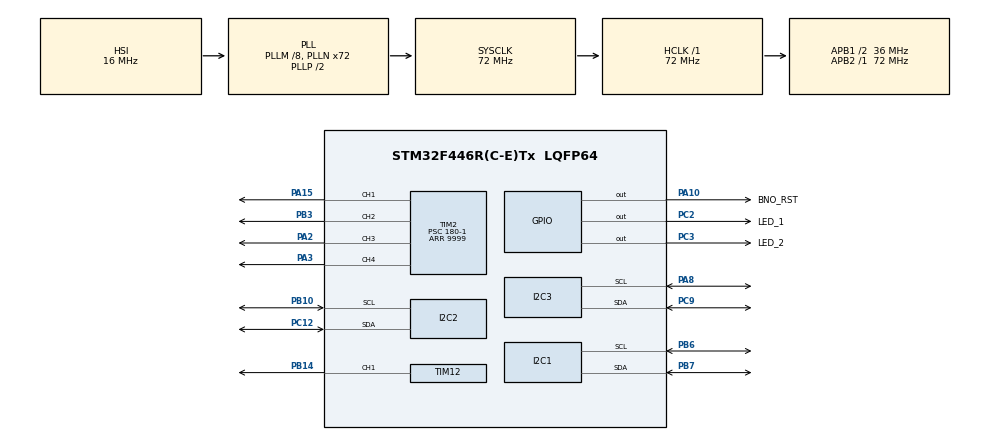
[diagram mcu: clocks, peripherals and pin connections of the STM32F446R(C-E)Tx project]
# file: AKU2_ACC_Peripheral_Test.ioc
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Mcu.Family=STM32F4
Mcu.Name=STM32F446R(C-E)Tx
Mcu.Package=LQFP64
NVIC.PriorityGroup=NVIC_PRIORITYGROUP_4
NVIC.TIM1_UP_TIM10_IRQn=true\:15\:0\:false\:false\:true\:false\:true\:true
NVIC.TimeBase=TIM1_UP_TIM10_IRQn
NVIC.TimeBaseIP=TIM1
PA10.GPIO_Label=BNO_RST
PA10.GPIO_PuPd=GPIO_PULLUP
PA10.PinState=GPIO_PIN_RESET
PA10.Signal=GPIO_Output
PA13.GPIO_Label=TMS
PA13.Mode=Serial_Wire
PA13.Signal=SYS_JTMS-SWDIO
PA14.GPIO_Label=TCK
PA14.Mode=Serial_Wire
PA14.Signal=SYS_JTCK-SWCLK
PA15.Signal=S_TIM2_CH1_ETR
PA2.Signal=S_TIM2_CH3
PA3.Signal=S_TIM2_CH4
PA8.Mode=I2C
PA8.Signal=I2C3_SCL
PB10.Mode=I2C
PB10.Signal=I2C2_SCL
PB14.Signal=S_TIM12_CH1
PB3.Signal=S_TIM2_CH2
PB6.Mode=I2C
PB6.Signal=I2C1_SCL
PB7.Mode=I2C
PB7.Signal=I2C1_SDA
PC12.Mode=I2C
PC12.Signal=I2C2_SDA
PC2.GPIO_Label=LED_1
PC2.Signal=GPIO_Output
PC3.GPIO_Label=LED_2
PC3.Signal=GPIO_Output
PC9.Mode=I2C
PC9.Signal=I2C3_SDA
ProjectManager.HeapSize=0x200
ProjectManager.StackSize=0x400
ProjectManager.TargetToolchain=STM32CubeIDE
RCC.48MHZClocksFreq_Value=84000000
RCC.AHBFreq_Value=72000000
RCC.APB1CLKDivider=RCC_HCLK_DIV2
RCC.APB1Freq_Value=36000000
RCC.APB1TimFreq_Value=72000000
RCC.APB2Freq_Value=72000000
RCC.APB2TimFreq_Value=72000000
RCC.CortexFreq_Value=72000000
RCC.FLatency-AdvancedSettings=FLASH_LATENCY_2
RCC.HCLKFreq_Value=72000000
RCC.HSE_VALUE=8000000
RCC.HSI_VALUE=16000000
RCC.PLLM=8
RCC.PLLN=72
RCC.PLLQ=3
RCC.PLLSourceVirtual=RCC_PLLSOURCE_HSI
RCC.SYSCLKFreq_VALUE=72000000
RCC.SYSCLKSource=RCC_SYSCLKSOURCE_PLLCLK
RCC.USBFreq_Value=48000000
RCC.VCOOutputFreq_Value=144000000
SH.S_TIM12_CH1.0=TIM12_CH1,PWM Generation1 CH1
SH.S_TIM2_CH1_ETR.0=TIM2_CH1,PWM Generation1 CH1
SH.S_TIM2_CH2.0=TIM2_CH2,PWM Generation2 CH2
SH.S_TIM2_CH3.0=TIM2_CH3,PWM Generation3 CH3
SH.S_TIM2_CH4.0=TIM2_CH4,PWM Generation4 CH4
TIM12.Channel-PWM\ Generation1\ CH1=TIM_CHANNEL_1
TIM12.Period=9999
TIM12.Prescaler=180-1
TIM2.Channel-PWM\ Generation1\ CH1=TIM_CHANNEL_1
TIM2.Channel-PWM\ Generation2\ CH2=TIM_CHANNEL_2
TIM2.Channel-PWM\ Generation3\ CH3=TIM_CHANNEL_3
TIM2.Channel-PWM\ Generation4\ CH4=TIM_CHANNEL_4
TIM2.Period=9999
TIM2.Prescaler=180-1
VP_SYS_VS_tim1.Mode=TIM1
board=NUCLEO-F446RE

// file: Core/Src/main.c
/* USER CODE BEGIN Header */
/**
  ******************************************************************************
  * @file           : main.c
  * @brief          : Main program body
  ******************************************************************************
  * @attention
  *
  * Copyright (c) 2024 STMicroelectronics.
  * All rights reserved.
  *
  * This software is licensed under terms that can be found in the LICENSE file
  * in the root directory of this software component.
  * If no LICENSE file comes with this software, it is provided AS-IS.
  *
  ******************************************************************************
  */
/* USER CODE END Header */
#include "main.h"
#include "i2c.h"
#include "tim.h"
#include "gpio.h"

void SystemClock_Config(void);

int main(void)
{

  /* MCU Configuration--------------------------------------------------------*/

  /* Reset of all peripherals, Initializes the Flash interface and the Systick. */
  HAL_Init();

  /* Configure the system clock */
  SystemClock_Config();

  /* Initialize all configured peripherals */
  MX_GPIO_Init();
  MX_I2C1_Init();
  MX_I2C3_Init();
  MX_TIM2_Init();
  MX_TIM12_Init();
  MX_I2C2_Init();
  /* USER CODE BEGIN 2 */
  init_bhi360();
  /* USER CODE END 2 */

  /* Infinite loop */
  /* USER CODE BEGIN WHILE */
  while (1)
  {
	  read_bhi360();
    /* USER CODE END WHILE */

  }
}

void SystemClock_Config(void)
{
  RCC_OscInitTypeDef RCC_OscInitStruct = {0};
  RCC_ClkInitTypeDef RCC_ClkInitStruct = {0};

  /** Configure the main internal regulator output voltage
  */
  __HAL_RCC_PWR_CLK_ENABLE();
  __HAL_PWR_VOLTAGESCALING_CONFIG(PWR_REGULATOR_VOLTAGE_SCALE3);

  /** Initializes the RCC Oscillators according to the specified parameters
  * in the RCC_OscInitTypeDef structure.
  */
  RCC_OscInitStruct.OscillatorType = RCC_OSCILLATORTYPE_HSI;
  RCC_OscInitStruct.HSIState = RCC_HSI_ON;
  RCC_OscInitStruct.HSICalibrationValue = RCC_HSICALIBRATION_DEFAULT;
  RCC_OscInitStruct.PLL.PLLState = RCC_PLL_ON;
  RCC_OscInitStruct.PLL.PLLSource = RCC_PLLSOURCE_HSI;
  RCC_OscInitStruct.PLL.PLLM = 8;
  RCC_OscInitStruct.PLL.PLLN = 72;
  RCC_OscInitStruct.PLL.PLLP = RCC_PLLP_DIV2;
  RCC_OscInitStruct.PLL.PLLQ = 3;
  RCC_OscInitStruct.PLL.PLLR = 2;
  if (HAL_RCC_OscConfig(&RCC_OscInitStruct) != HAL_OK)
  {
    Error_Handler();
  }

  /** Initializes the CPU, AHB and APB buses clocks
  */
  RCC_ClkInitStruct.ClockType = RCC_CLOCKTYPE_HCLK|RCC_CLOCKTYPE_SYSCLK
                              |RCC_CLOCKTYPE_PCLK1|RCC_CLOCKTYPE_PCLK2;
  RCC_ClkInitStruct.SYSCLKSource = RCC_SYSCLKSOURCE_PLLCLK;
  RCC_ClkInitStruct.AHBCLKDivider = RCC_SYSCLK_DIV1;
  RCC_ClkInitStruct.APB1CLKDivider = RCC_HCLK_DIV2;
  RCC_ClkInitStruct.APB2CLKDivider = RCC_HCLK_DIV1;

  if (HAL_RCC_ClockConfig(&RCC_ClkInitStruct, FLASH_LATENCY_2) != HAL_OK)
  {
    Error_Handler();
  }
}

void HAL_TIM_PeriodElapsedCallback(TIM_HandleTypeDef *htim)
{
  if (htim->Instance == TIM1) {
    HAL_IncTick();
  }
}

void Error_Handler(void)
{
  __disable_irq();
  while (1)
  {
  }
}
